# SAM9X60 device description
Architecture: ARM926EJS; Family: SAM9; Series: SAM9X
Registers are 32-bit, read-write, no defined reset value unless marked. A register's access mark holds for its fields unless they carry their own. Offsets are from the block's base; [hi:lo] are bit positions; lines under a group give offsets from that group; {n}, {i} and the like mark numbered series.

## XDMAC — Extensible DMA Controller
Instances: XDMAC 0xF0008000
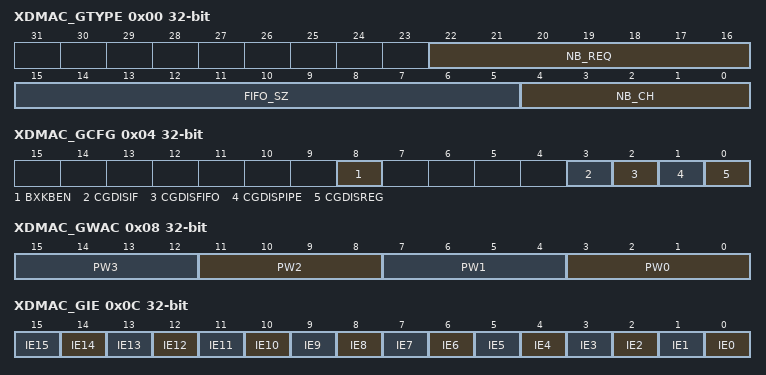
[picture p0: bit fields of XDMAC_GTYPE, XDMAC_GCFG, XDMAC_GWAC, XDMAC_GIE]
0x00 XDMAC_GTYPE ro — Global Type Register
  [22:16] NB_REQ — Number of Peripheral Requests Minus One
  [15:5] FIFO_SZ — Number of Bytes
  [4:0] NB_CH — Number of Channels Minus One
0x04 XDMAC_GCFG — Global Configuration Register
  [8] BXKBEN — Boundary X Kilobyte Enable
  [3] CGDISIF — Bus Interface Clock Gating Disable
  [2] CGDISFIFO — FIFO Clock Gating Disable
  [1] CGDISPIPE — Pipeline Clock Gating Disable
  [0] CGDISREG — Configuration Registers Clock Gating Disable
0x08 XDMAC_GWAC — Global Weighted Arbiter Configuration Register
  [4n+3:4n] PW{n} (n=0..3) — Pool Weight {n}
0x0C XDMAC_GIE wo — Global Interrupt Enable Register
  [n] IE{n} (n=0..15) — XDMAC Channel {n} Interrupt Enable
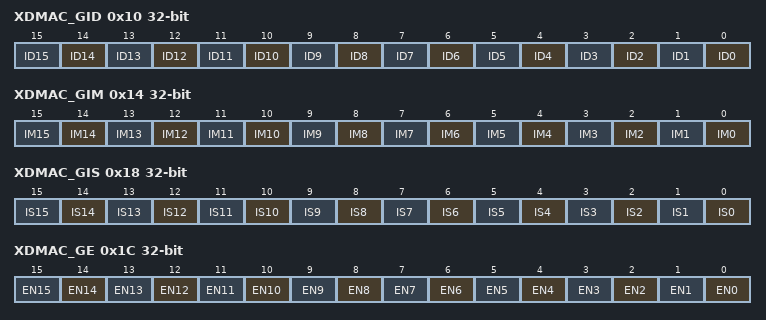
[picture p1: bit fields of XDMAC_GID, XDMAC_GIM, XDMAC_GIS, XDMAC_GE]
0x10 XDMAC_GID wo — Global Interrupt Disable Register
  [n] ID{n} (n=0..15) — XDMAC Channel {n} Interrupt Disable
0x14 XDMAC_GIM ro — Global Interrupt Mask Register
  [n] IM{n} (n=0..15) — XDMAC Channel {n} Interrupt Mask
0x18 XDMAC_GIS ro — Global Interrupt Status Register
  [n] IS{n} (n=0..15) — XDMAC Channel {n} Interrupt Status
0x1C XDMAC_GE wo — Global Channel Enable Register
  [n] EN{n} (n=0..15) — XDMAC Channel {n} Enable
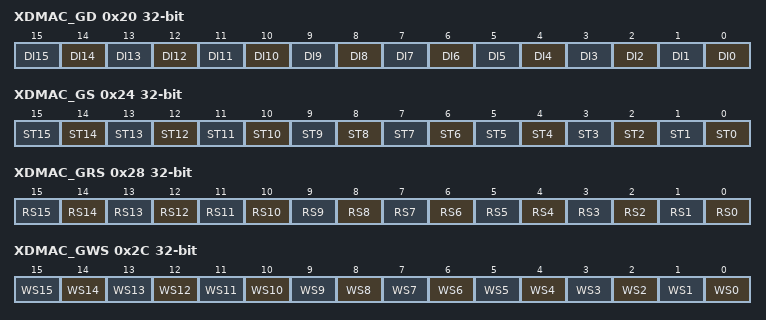
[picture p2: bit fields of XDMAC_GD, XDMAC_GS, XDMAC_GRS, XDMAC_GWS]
0x20 XDMAC_GD wo — Global Channel Disable Register
  [n] DI{n} (n=0..15) — XDMAC Channel {n} Disable
0x24 XDMAC_GS ro — Global Channel Status Register
  [n] ST{n} (n=0..15) — XDMAC Channel {n} Status
0x28 XDMAC_GRS — Global Channel Read Suspend Register
  [n] RS{n} (n=0..15) — XDMAC Channel {n} Read Suspend
0x2C XDMAC_GWS — Global Channel Write Suspend Register
  [n] WS{n} (n=0..15) — XDMAC Channel {n} Write Suspend
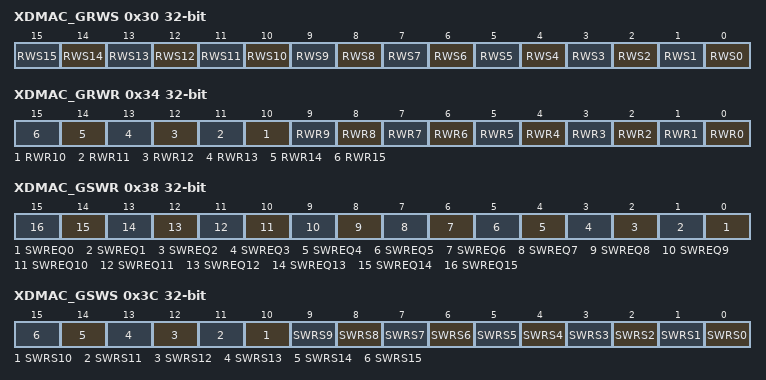
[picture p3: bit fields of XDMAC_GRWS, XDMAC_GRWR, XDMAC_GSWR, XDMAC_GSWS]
0x30 XDMAC_GRWS wo — Global Channel Read Write Suspend Register
  [n] RWS{n} (n=0..15) — XDMAC Channel {n} Read Write Suspend
0x34 XDMAC_GRWR wo — Global Channel Read Write Resume Register
  [n] RWR{n} (n=0..15) — XDMAC Channel {n} Read Write Resume
0x38 XDMAC_GSWR wo — Global Channel Software Request Register
  [n] SWREQ{n} (n=0..15) — XDMAC Channel {n} Software Request
0x3C XDMAC_GSWS ro — Global Channel Software Request Status Register
  [n] SWRS{n} (n=0..15) — XDMAC Channel {n} Software Request Status
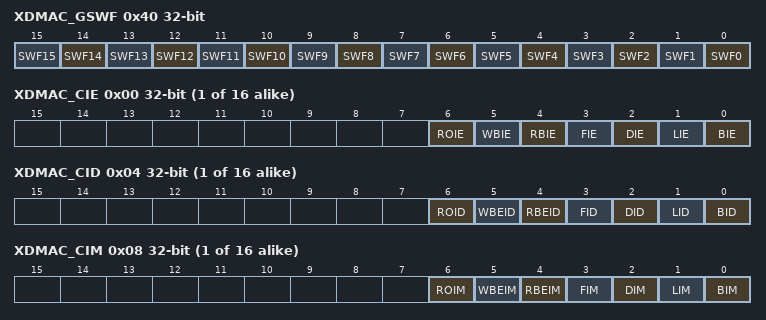
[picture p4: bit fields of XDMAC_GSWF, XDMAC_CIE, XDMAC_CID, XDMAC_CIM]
0x40 XDMAC_GSWF wo — Global Channel Software Flush Request Register
  [n] SWF{n} (n=0..15) — XDMAC Channel {n} Software Flush Request
{0x50+0x40*i} XDMAC_CHID[{i}] (i=0..15) group
  0x00 XDMAC_CIE wo — Channel Interrupt Enable Register
    [6] ROIE — Request Overflow Error Interrupt Enable
    [5] WBIE — Write Bus Error Interrupt Enable
    [4] RBIE — Read Bus Error Interrupt Enable
    [3] FIE — End of Flush Interrupt Enable
    [2] DIE — End of Disable Interrupt Enable
    [1] LIE — End of Linked List Interrupt Enable
    [0] BIE — End of Block Interrupt Enable
  0x04 XDMAC_CID wo — Channel Interrupt Disable Register
    [6] ROID — Request Overflow Error Interrupt Disable
    [5] WBEID — Write Bus Error Interrupt Disable
    [4] RBEID — Read Bus Error Interrupt Disable
    [3] FID — End of Flush Interrupt Disable
    [2] DID — End of Disable Interrupt Disable
    [1] LID — End of Linked List Interrupt Disable
    [0] BID — End of Block Interrupt Disable
  0x08 XDMAC_CIM ro — Channel Interrupt Mask Register
    [6] ROIM — Request Overflow Error Interrupt Mask
    [5] WBEIM — Write Bus Error Interrupt Mask
    [4] RBEIM — Read Bus Error Interrupt Mask
    [3] FIM — End of Flush Interrupt Mask
    [2] DIM — End of Disable Interrupt Mask
    [1] LIM — End of Linked List Interrupt Mask
    [0] BIM — End of Block Interrupt Mask
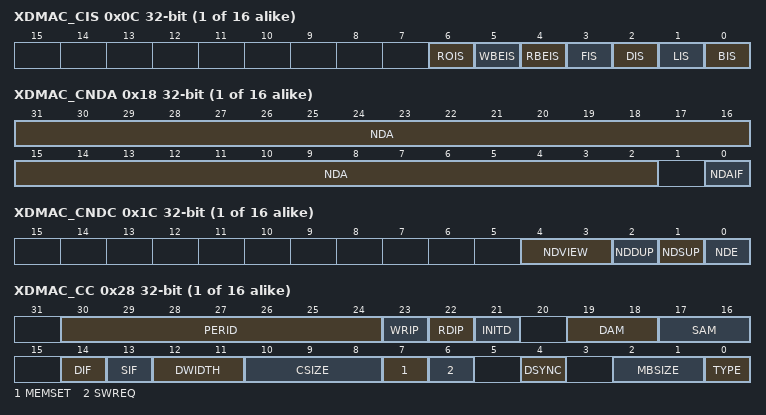
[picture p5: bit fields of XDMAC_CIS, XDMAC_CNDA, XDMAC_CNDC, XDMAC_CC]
  0x0C XDMAC_CIS ro — Channel Interrupt Status Register
    [6] ROIS — Request Overflow Error Interrupt Status
    [5] WBEIS — Write Bus Error Interrupt Status
    [4] RBEIS — Read Bus Error Interrupt Status
    [3] FIS — End of Flush Interrupt Status
    [2] DIS — End of Disable Interrupt Status
    [1] LIS — End of Linked List Interrupt Status
    [0] BIS — End of Block Interrupt Status
  0x10 XDMAC_CSA — Channel Source Address Register
    [31:0] SA — Channel x Source Address
  0x14 XDMAC_CDA — Channel Destination Address Register
    [31:0] DA — Channel x Destination Address
  0x18 XDMAC_CNDA — Channel Next Descriptor Address Register
    [31:2] NDA — Channel x Next Descriptor Address
    [0] NDAIF — Channel x Next Descriptor Interface
  0x1C XDMAC_CNDC — Channel Next Descriptor Control Register
    [4:3] NDVIEW — Channel x Next Descriptor View
      {v}=NDV{v} (Next Descriptor View {v}) (v=0..3)
    [2] NDDUP — Channel x Next Descriptor Destination Update
      0=DST_PARAMS_UNCHANGED (Destination parameters remain unchanged.); 1=DST_PARAMS_UPDATED (Destination parameters are updated when the descriptor is retrieved.)
    [1] NDSUP — Channel x Next Descriptor Source Update
      0=SRC_PARAMS_UNCHANGED (Source parameters remain unchanged.); 1=SRC_PARAMS_UPDATED (Source parameters are updated when the descriptor is retrieved.)
    [0] NDE — Channel x Next Descriptor Enable
      0=DSCR_FETCH_DIS (Descriptor fetch is disabled.); 1=DSCR_FETCH_EN (Descriptor fetch is enabled.)
  0x20 XDMAC_CUBC — Channel Microblock Control Register
    [23:0] UBLEN — Channel x Microblock Length
  0x24 XDMAC_CBC — Channel Block Control Register
    [11:0] BLEN — Channel x Block Length
  0x28 XDMAC_CC — Channel Configuration Register
    [30:24] PERID — Channel x Peripheral Hardware Request Line Identifier
    [23] WRIP — Write in Progress (this bit is read-only)
      0=DONE (No active write transaction on the bus.); 1=IN_PROGRESS (A write transaction is in progress.)
    [22] RDIP — Read in Progress (this bit is read-only)
      0=DONE (No active read transaction on the bus.); 1=IN_PROGRESS (A read transaction is in progress.)
    [21] INITD — Channel Initialization Done (this bit is read-only)
      0=IN_PROGRESS (Channel initialization is in progress.); 1=TERMINATED (Channel initialization is completed.)
    [19:18] DAM — Channel x Destination Addressing Mode
      0=FIXED_AM (The address remains unchanged.); 1=INCREMENTED_AM (The addressing mode is incremented (the increment size is set to the data size).); 2=UBS_AM (The microblock stride is added at the microblock boundary.); 3=UBS_DS_AM (The microblock stride is added at the microblock boundary; the data stride is added at the data boundary.)
    [17:16] SAM — Channel x Source Addressing Mode
      0=FIXED_AM (The address remains unchanged.); 1=INCREMENTED_AM (The addressing mode is incremented (the increment size is set to the data size).); 2=UBS_AM (The microblock stride is added at the microblock boundary.); 3=UBS_DS_AM (The microblock stride is added at the microblock boundary, the data stride is added at the data boundary.)
    [14] DIF — Channel x Destination Interface Identifier
      0=AHB_IF0 (The data is written through system bus interface 0.); 1=AHB_IF1 (The data is written though system bus interface 1.)
    [13] SIF — Channel x Source Interface Identifier
      0=AHB_IF0 (The data is read through system bus interface 0.); 1=AHB_IF1 (The data is read through system bus interface 1.)
    [12:11] DWIDTH — Channel x Data Width
      0=BYTE (The data size is set to 8 bits); 1=HALFWORD (The data size is set to 16 bits); 2=WORD (The data size is set to 32 bits)
    [10:8] CSIZE — Channel x Chunk Size
      0=CHK_1 (1 data transferred); 1=CHK_2 (2 data transferred); 2=CHK_4 (4 data transferred); 3=CHK_8 (8 data transferred); 4=CHK_16 (16 data transferred)
    [7] MEMSET — Channel x Fill Block of Memory
      0=NORMAL_MODE (Memset is not activated.); 1=HW_MODE (Sets the block of memory pointed by DA field to the specified value. This operation is performed on 8-, 16- or 32-bit basis.)
    [6] SWREQ — Channel x Software Request Trigger
      0=HWR_CONNECTED (Hardware request line is connected to the peripheral request line.); 1=SWR_CONNECTED (Software request is connected to the peripheral request line.)
    [4] DSYNC — Channel x Synchronization
      0=PER2MEM (Peripheral-to-memory transfer.); 1=MEM2PER (Memory-to-peripheral transfer)
    [2:1] MBSIZE — Channel x Memory Burst Size
      0=SINGLE (The memory burst size is set to one.); 1=FOUR (The memory burst size is set to four.); 2=EIGHT (The memory burst size is set to eight.); 3=SIXTEEN (The memory burst size is set to sixteen.)
    [0] TYPE — Channel x Transfer Type
      0=MEM_TRAN (Self-triggered mode (memory-to-memory transfer).); 1=PER_TRAN (Synchronized mode (peripheral-to-memory or memory-to-peripheral transfer).)
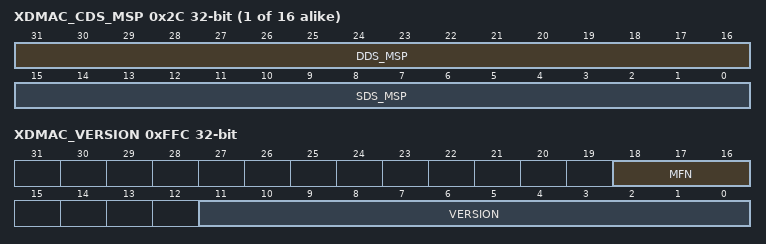
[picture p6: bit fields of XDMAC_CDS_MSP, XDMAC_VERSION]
  0x2C XDMAC_CDS_MSP — Channel Data Stride Memory Set Pattern
    [31:16] DDS_MSP — Channel x Destination Data Stride or Memory Set Pattern
    [15:0] SDS_MSP — Channel x Source Data stride or Memory Set Pattern
  0x30 XDMAC_CSUS — Channel Source Microblock Stride
    [23:0] SUBS — Channel x Source Microblock Stride
  0x34 XDMAC_CDUS — Channel Destination Microblock Stride
    [23:0] DUBS — Channel x Destination Microblock Stride
0xFFC XDMAC_VERSION ro
  [18:16] MFN — Metal Fix Number
  [11:0] VERSION — Version of the Hardware Module
